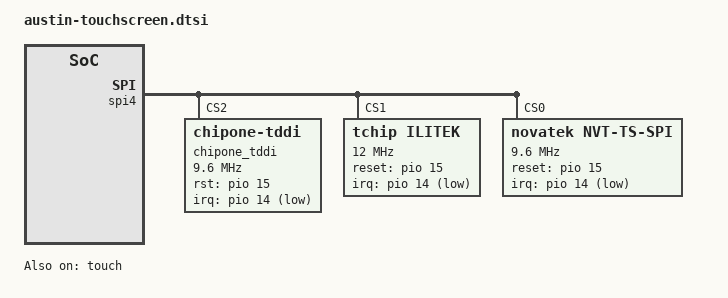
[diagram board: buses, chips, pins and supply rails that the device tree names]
/*
 * Copyright (C) 2010 - 2018 Novatek, Inc.
 *
 * $Revision$
 * $Date$
 *
 * This program is free software; you can redistribute it and/or modify
 * it under the terms of the GNU General Public License as published by
 * the Free Software Foundation; either version 2 of the License, or
 * (at your option) any later version.
 *
 * This program is distributed in the hope that it will be useful, but WITHOUT
 * ANY WARRANTY; without even the implied warranty of MERCHANTABILITY or
 * FITNESS FOR A PARTICULAR PURPOSE.  See the GNU General Public License for
 * more details.
 *
 */

&touch {
	tpd-resolution = <720 1600>;
	interrupt-parent = <&pio>;
	interrupts = <14 IRQ_TYPE_EDGE_RISING 14 0>;
	use-tpd-button = <0>;
	tpd-key-num = <3>;
	tpd-key-local= <139 172 158 0>;
	tpd-key-dim-local = <90 883 100 40 230
				 883 100 40 370 883 100 40 0 0 0 0>;
	tpd-max-touch-num = <10>;
	tpd-filter-enable = <0>;
	tpd-filter-pixel-density = <106>;
	tpd-filter-custom-prameters = <0 0 0 0 0 0 0 0 0 0 0 0>;
	tpd-filter-custom-speed = <0 0 0>;
	pinctrl-names = "default", "state_eint_as_int", "state_eint_output0",
		"state_eint_output1", "state_rst_output0", "state_rst_output1";
	pinctrl-0 = <&ctp_pins_default>;
	pinctrl-1 = <&ctp_pins_eint_as_int>;
	pinctrl-2 = <&ctp_pins_eint_output0>;
	pinctrl-3 = <&ctp_pins_eint_output1>;
	pinctrl-4 = <&ctp_pins_rst_output0>;
	pinctrl-5 = <&ctp_pins_rst_output1>;
	status = "okay";
};

&pio {
	ctp_pins_default: eint0default {
	};
	ctp_pins_eint_as_int: eint@0 {
		pins_cmd_dat {
			pinmux = <PINMUX_GPIO14__FUNC_GPIO14>;
			input-enable;
		};
	};
	ctp_pins_eint_output0: eintoutput0 {
		pins_cmd_dat {
			pinmux = <PINMUX_GPIO14__FUNC_GPIO14>;
			output-low;
		};
	};
	ctp_pins_eint_output1: eintoutput1 {
		pins_cmd_dat {
			pinmux = <PINMUX_GPIO14__FUNC_GPIO14>;
			output-high;
		};
	};
	ctp_pins_rst_output0: rstoutput0 {
		pins_cmd_dat {
			pinmux = <PINMUX_GPIO15__FUNC_GPIO15>;
			output-low;
		};
	};
	ctp_pins_rst_output1: rstoutput1 {
		pins_cmd_dat {
			pinmux = <PINMUX_GPIO15__FUNC_GPIO15>;
			output-high;
		};
	};
};

&spi4 {
	status = "okay";
	/delete-property/mediatek,pad-select;
	mediatek,pad-select = <0>,<0>,<0>;
	cs-gpios = <0>,<0>,<0>;

	chipone_tddi@2 {
		compatible = "chipone-tddi";
		reg = <2>;
		status = "okay";
		spi-max-frequency = <9600000>;
		chipone,rst-gpio = <&pio 15 0x00>;
		chipone,irq-gpio = <&pio 14 0x2001>;

		touch,max-touch-number = <10>;
		touch,display-coords =  <0 0 720 1600>;
		chipone,x-res = <720>;
		chipone,y-res = <1600>;

		chipone,test-reset-pin;
		chipone,test-rawdata;
		chipone,test-rawdata-frames = <1>;
		chipone,rawdata-min = <1560>;
		chipone,rawdata-max = <2860>;
		chipone,test-noise;
		chipone,test-noise-frames = <16>;
		chipone,noise-max = <70>;
		chipone,test-open;
		chipone,open-min = <3100>;
		chipone,test-short;
		chipone,short-min = <500>;

		chipone,test-compensate-cap;
		chipone,compensate-cap-min = <1>;
		chipone,compensate-cap-max = <126>;

		chipone,touch-charger-detect-enable;
		chipone,touch-charger-detect-type = "notify";
		chipone,touch-charger-detect-psy-name = "usb";
		chipone,touch-charger-detect-psp = "POWER_SUPPLY_PROP_ONLINE";
		chipone,touch-charger-detect-psp-poll-interval = <1000>;

		chipone,touch-earjack-detect-enable;
		chipone,touch-earjack-state-filepath = "/sys/bus/platform/drivers/Accdet_Driver/state";
		chipone,touch-earjack-poll-interval = <1000>;
	};

	ilitek@1{
		compatible = "tchip,ilitek";
		reg = <1>;
		spi-max-frequency = <12000000>;
		touch,reset-gpio = <&pio 15 0x00>;
		touch,irq-gpio = <&pio 14 0x2001>;

		status = "okay";
	};

	/* Novatek device tree node */
	novatek@0 {
		compatible = "novatek,NVT-ts-spi";
		reg = <0>; //Same as CS ID
		status = "ok";

		spi-max-frequency = <9600000>;	//4800000,9600000,15000000,19200000
		novatek,reset-gpio = <&pio 15 0x00>;
		novatek,irq-gpio = <&pio 14 0x2001>;

		/* 525 */
		//novatek,swrst-n8-addr = <0x01F01A>;

		/* 672A, 525B, 675, 526, 672C */
		novatek,swrst-n8-addr = <0x03F0FE>;
		novatek,spi-rd-fast-addr = <0x03F310>;

		/* MP */
		//novatek,mp-support-dt;

		novatek,def-config-id = <0x6503>;

		novatek-mp-criteria-nvtpid@0 {
			#address-cells = <1>;
			#size-cells = <0>;
			compatible = "novatek-mp-criteria-nvtpid";

			/* MP Config */
			IC_X_CFG_SIZE = <18>;
			IC_Y_CFG_SIZE = <36>;
			IC_KEY_CFG_SIZE = <4>;
			X_Channel = <18>;
			Y_Channel = <36>;
			AIN_X = <0 1 2 3 4 5 6 7 8 9 10 11 12 13 14 15 16 17>;
			AIN_Y = <0 1 2 3 4 5 6 7 8 9 10 11 12 13 14 15 16 17
						18 19 20 21 22 23 24 25 26 27 28 29 30 31 32 33 34 35>;
			AIN_KEY = <0 1 2 0xFF>;

			/* MP Criteria */
			PS_Config_Lmt_Short_Rawdata_P = <
				14008 14008 14008 14008 14008 14008 14008 14008 14008 14008 14008 14008 14008 14008 14008 14008 14008 14008
				14008 14008 14008 14008 14008 14008 14008 14008 14008 14008 14008 14008 14008 14008 14008 14008 14008 14008
				14008 14008 14008 14008 14008 14008 14008 14008 14008 14008 14008 14008 14008 14008 14008 14008 14008 14008
				14008 14008 14008 14008 14008 14008 14008 14008 14008 14008 14008 14008 14008 14008 14008 14008 14008 14008
				14008 14008 14008 14008 14008 14008 14008 14008 14008 14008 14008 14008 14008 14008 14008 14008 14008 14008
				14008 14008 14008 14008 14008 14008 14008 14008 14008 14008 14008 14008 14008 14008 14008 14008 14008 14008
				14008 14008 14008 14008 14008 14008 14008 14008 14008 14008 14008 14008 14008 14008 14008 14008 14008 14008
				14008 14008 14008 14008 14008 14008 14008 14008 14008 14008 14008 14008 14008 14008 14008 14008 14008 14008
				14008 14008 14008 14008 14008 14008 14008 14008 14008 14008 14008 14008 14008 14008 14008 14008 14008 14008
				14008 14008 14008 14008 14008 14008 14008 14008 14008 14008 14008 14008 14008 14008 14008 14008 14008 14008
				14008 14008 14008 14008 14008 14008 14008 14008 14008 14008 14008 14008 14008 14008 14008 14008 14008 14008
				14008 14008 14008 14008 14008 14008 14008 14008 14008 14008 14008 14008 14008 14008 14008 14008 14008 14008
				14008 14008 14008 14008 14008 14008 14008 14008 14008 14008 14008 14008 14008 14008 14008 14008 14008 14008
				14008 14008 14008 14008 14008 14008 14008 14008 14008 14008 14008 14008 14008 14008 14008 14008 14008 14008
				14008 14008 14008 14008 14008 14008 14008 14008 14008 14008 14008 14008 14008 14008 14008 14008 14008 14008
				14008 14008 14008 14008 14008 14008 14008 14008 14008 14008 14008 14008 14008 14008 14008 14008 14008 14008
				14008 14008 14008 14008 14008 14008 14008 14008 14008 14008 14008 14008 14008 14008 14008 14008 14008 14008
				14008 14008 14008 14008 14008 14008 14008 14008 14008 14008 14008 14008 14008 14008 14008 14008 14008 14008
				14008 14008 14008 14008 14008 14008 14008 14008 14008 14008 14008 14008 14008 14008 14008 14008 14008 14008
				14008 14008 14008 14008 14008 14008 14008 14008 14008 14008 14008 14008 14008 14008 14008 14008 14008 14008
				14008 14008 14008 14008 14008 14008 14008 14008 14008 14008 14008 14008 14008 14008 14008 14008 14008 14008
				14008 14008 14008 14008 14008 14008 14008 14008 14008 14008 14008 14008 14008 14008 14008 14008 14008 14008
				14008 14008 14008 14008 14008 14008 14008 14008 14008 14008 14008 14008 14008 14008 14008 14008 14008 14008
				14008 14008 14008 14008 14008 14008 14008 14008 14008 14008 14008 14008 14008 14008 14008 14008 14008 14008
				14008 14008 14008 14008 14008 14008 14008 14008 14008 14008 14008 14008 14008 14008 14008 14008 14008 14008
				14008 14008 14008 14008 14008 14008 14008 14008 14008 14008 14008 14008 14008 14008 14008 14008 14008 14008
				14008 14008 14008 14008 14008 14008 14008 14008 14008 14008 14008 14008 14008 14008 14008 14008 14008 14008
				14008 14008 14008 14008 14008 14008 14008 14008 14008 14008 14008 14008 14008 14008 14008 14008 14008 14008
				14008 14008 14008 14008 14008 14008 14008 14008 14008 14008 14008 14008 14008 14008 14008 14008 14008 14008
				14008 14008 14008 14008 14008 14008 14008 14008 14008 14008 14008 14008 14008 14008 14008 14008 14008 14008
				14008 14008 14008 14008 14008 14008 14008 14008 14008 14008 14008 14008 14008 14008 14008 14008 14008 14008
				14008 14008 14008 14008 14008 14008 14008 14008 14008 14008 14008 14008 14008 14008 14008 14008 14008 14008
				14008 14008 14008 14008 14008 14008 14008 14008 14008 14008 14008 14008 14008 14008 14008 14008 14008 14008
				14008 14008 14008 14008 14008 14008 14008 14008 14008 14008 14008 14008 14008 14008 14008 14008 14008 14008
				14008 14008 14008 14008 14008 14008 14008 14008 14008 14008 14008 14008 14008 14008 14008 14008 14008 14008
				14008 14008 14008 14008 14008 14008 14008 14008 14008 14008 14008 14008 14008 14008 14008 14008 14008 14008
				14008 14008 14008>;

			PS_Config_Lmt_Short_Rawdata_N = <
				10000 10000 10000 10000 10000 10000 10000 10000 10000 10000 10000 10000 10000 10000 10000 10000 10000 10000
				10000 10000 10000 10000 10000 10000 10000 10000 10000 10000 10000 10000 10000 10000 10000 10000 10000 10000
				10000 10000 10000 10000 10000 10000 10000 10000 10000 10000 10000 10000 10000 10000 10000 10000 10000 10000
				10000 10000 10000 10000 10000 10000 10000 10000 10000 10000 10000 10000 10000 10000 10000 10000 10000 10000
				10000 10000 10000 10000 10000 10000 10000 10000 10000 10000 10000 10000 10000 10000 10000 10000 10000 10000
				10000 10000 10000 10000 10000 10000 10000 10000 10000 10000 10000 10000 10000 10000 10000 10000 10000 10000
				10000 10000 10000 10000 10000 10000 10000 10000 10000 10000 10000 10000 10000 10000 10000 10000 10000 10000
				10000 10000 10000 10000 10000 10000 10000 10000 10000 10000 10000 10000 10000 10000 10000 10000 10000 10000
				10000 10000 10000 10000 10000 10000 10000 10000 10000 10000 10000 10000 10000 10000 10000 10000 10000 10000
				10000 10000 10000 10000 10000 10000 10000 10000 10000 10000 10000 10000 10000 10000 10000 10000 10000 10000
				10000 10000 10000 10000 10000 10000 10000 10000 10000 10000 10000 10000 10000 10000 10000 10000 10000 10000
				10000 10000 10000 10000 10000 10000 10000 10000 10000 10000 10000 10000 10000 10000 10000 10000 10000 10000
				10000 10000 10000 10000 10000 10000 10000 10000 10000 10000 10000 10000 10000 10000 10000 10000 10000 10000
				10000 10000 10000 10000 10000 10000 10000 10000 10000 10000 10000 10000 10000 10000 10000 10000 10000 10000
				10000 10000 10000 10000 10000 10000 10000 10000 10000 10000 10000 10000 10000 10000 10000 10000 10000 10000
				10000 10000 10000 10000 10000 10000 10000 10000 10000 10000 10000 10000 10000 10000 10000 10000 10000 10000
				10000 10000 10000 10000 10000 10000 10000 10000 10000 10000 10000 10000 10000 10000 10000 10000 10000 10000
				10000 10000 10000 10000 10000 10000 10000 10000 10000 10000 10000 10000 10000 10000 10000 10000 10000 10000
				10000 10000 10000 10000 10000 10000 10000 10000 10000 10000 10000 10000 10000 10000 10000 10000 10000 10000
				10000 10000 10000 10000 10000 10000 10000 10000 10000 10000 10000 10000 10000 10000 10000 10000 10000 10000
				10000 10000 10000 10000 10000 10000 10000 10000 10000 10000 10000 10000 10000 10000 10000 10000 10000 10000
				10000 10000 10000 10000 10000 10000 10000 10000 10000 10000 10000 10000 10000 10000 10000 10000 10000 10000
				10000 10000 10000 10000 10000 10000 10000 10000 10000 10000 10000 10000 10000 10000 10000 10000 10000 10000
				10000 10000 10000 10000 10000 10000 10000 10000 10000 10000 10000 10000 10000 10000 10000 10000 10000 10000
				10000 10000 10000 10000 10000 10000 10000 10000 10000 10000 10000 10000 10000 10000 10000 10000 10000 10000
				10000 10000 10000 10000 10000 10000 10000 10000 10000 10000 10000 10000 10000 10000 10000 10000 10000 10000
				10000 10000 10000 10000 10000 10000 10000 10000 10000 10000 10000 10000 10000 10000 10000 10000 10000 10000
				10000 10000 10000 10000 10000 10000 10000 10000 10000 10000 10000 10000 10000 10000 10000 10000 10000 10000
				10000 10000 10000 10000 10000 10000 10000 10000 10000 10000 10000 10000 10000 10000 10000 10000 10000 10000
				10000 10000 10000 10000 10000 10000 10000 10000 10000 10000 10000 10000 10000 10000 10000 10000 10000 10000
				10000 10000 10000 10000 10000 10000 10000 10000 10000 10000 10000 10000 10000 10000 10000 10000 10000 10000
				10000 10000 10000 10000 10000 10000 10000 10000 10000 10000 10000 10000 10000 10000 10000 10000 10000 10000
				10000 10000 10000 10000 10000 10000 10000 10000 10000 10000 10000 10000 10000 10000 10000 10000 10000 10000
				10000 10000 10000 10000 10000 10000 10000 10000 10000 10000 10000 10000 10000 10000 10000 10000 10000 10000
				10000 10000 10000 10000 10000 10000 10000 10000 10000 10000 10000 10000 10000 10000 10000 10000 10000 10000
				10000 10000 10000 10000 10000 10000 10000 10000 10000 10000 10000 10000 10000 10000 10000 10000 10000 10000
				10000 10000 10000>;

			PS_Config_Lmt_Open_Rawdata_P = <
				5120 5120 5120 5120 5120 5120 5120 5120 5120 5120 5120 5120 5120 5120 5120 5120 5120 5120
				5120 5120 5120 5120 5120 5120 5120 5120 5120 5120 5120 5120 5120 5120 5120 5120 5120 5120
				5120 5120 5120 5120 5120 5120 5120 5120 5120 5120 5120 5120 5120 5120 5120 5120 5120 5120
				5120 5120 5120 5120 5120 5120 5120 5120 5120 5120 5120 5120 5120 5120 5120 5120 5120 5120
				5120 5120 5120 5120 5120 5120 5120 5120 5120 5120 5120 5120 5120 5120 5120 5120 5120 5120
				5120 5120 5120 5120 5120 5120 5120 5120 5120 5120 5120 5120 5120 5120 5120 5120 5120 5120
				5120 5120 5120 5120 5120 5120 5120 5120 5120 5120 5120 5120 5120 5120 5120 5120 5120 5120
				5120 5120 5120 5120 5120 5120 5120 5120 5120 5120 5120 5120 5120 5120 5120 5120 5120 5120
				5120 5120 5120 5120 5120 5120 5120 5120 5120 5120 5120 5120 5120 5120 5120 5120 5120 5120
				5120 5120 5120 5120 5120 5120 5120 5120 5120 5120 5120 5120 5120 5120 5120 5120 5120 5120
				5120 5120 5120 5120 5120 5120 5120 5120 5120 5120 5120 5120 5120 5120 5120 5120 5120 5120
				5120 5120 5120 5120 5120 5120 5120 5120 5120 5120 5120 5120 5120 5120 5120 5120 5120 5120
				5120 5120 5120 5120 5120 5120 5120 5120 5120 5120 5120 5120 5120 5120 5120 5120 5120 5120
				5120 5120 5120 5120 5120 5120 5120 5120 5120 5120 5120 5120 5120 5120 5120 5120 5120 5120
				5120 5120 5120 5120 5120 5120 5120 5120 5120 5120 5120 5120 5120 5120 5120 5120 5120 5120
				5120 5120 5120 5120 5120 5120 5120 5120 5120 5120 5120 5120 5120 5120 5120 5120 5120 5120
				5120 5120 5120 5120 5120 5120 5120 5120 5120 5120 5120 5120 5120 5120 5120 5120 5120 5120
				5120 5120 5120 5120 5120 5120 5120 5120 5120 5120 5120 5120 5120 5120 5120 5120 5120 5120
				5120 5120 5120 5120 5120 5120 5120 5120 5120 5120 5120 5120 5120 5120 5120 5120 5120 5120
				5120 5120 5120 5120 5120 5120 5120 5120 5120 5120 5120 5120 5120 5120 5120 5120 5120 5120
				5120 5120 5120 5120 5120 5120 5120 5120 5120 5120 5120 5120 5120 5120 5120 5120 5120 5120
				5120 5120 5120 5120 5120 5120 5120 5120 5120 5120 5120 5120 5120 5120 5120 5120 5120 5120
				5120 5120 5120 5120 5120 5120 5120 5120 5120 5120 5120 5120 5120 5120 5120 5120 5120 5120
				5120 5120 5120 5120 5120 5120 5120 5120 5120 5120 5120 5120 5120 5120 5120 5120 5120 5120
				5120 5120 5120 5120 5120 5120 5120 5120 5120 5120 5120 5120 5120 5120 5120 5120 5120 5120
				5120 5120 5120 5120 5120 5120 5120 5120 5120 5120 5120 5120 5120 5120 5120 5120 5120 5120
				5120 5120 5120 5120 5120 5120 5120 5120 5120 5120 5120 5120 5120 5120 5120 5120 5120 5120
				5120 5120 5120 5120 5120 5120 5120 5120 5120 5120 5120 5120 5120 5120 5120 5120 5120 5120
				5120 5120 5120 5120 5120 5120 5120 5120 5120 5120 5120 5120 5120 5120 5120 5120 5120 5120
				5120 5120 5120 5120 5120 5120 5120 5120 5120 5120 5120 5120 5120 5120 5120 5120 5120 5120
				5120 5120 5120 5120 5120 5120 5120 5120 5120 5120 5120 5120 5120 5120 5120 5120 5120 5120
				5120 5120 5120 5120 5120 5120 5120 5120 5120 5120 5120 5120 5120 5120 5120 5120 5120 5120
				5120 5120 5120 5120 5120 5120 5120 5120 5120 5120 5120 5120 5120 5120 5120 5120 5120 5120
				5120 5120 5120 5120 5120 5120 5120 5120 5120 5120 5120 5120 5120 5120 5120 5120 5120 5120
				5120 5120 5120 5120 5120 5120 5120 5120 5120 5120 5120 5120 5120 5120 5120 5120 5120 5120
				5120 5120 5120 5120 5120 5120 5120 5120 5120 5120 5120 5120 5120 5120 5120 5120 5120 5120
				5120 5120 5120>;

			PS_Config_Lmt_Open_Rawdata_N = <
				(-511) (-511) (-511) (-511) (-511) (-511) (-511) (-511) (-511) (-511) (-511) (-511) (-511) (-511) (-511) (-511) (-511) (-511)
				(-511) (-511) (-511) (-511) (-511) (-511) (-511) (-511) (-511) (-511) (-511) (-511) (-511) (-511) (-511) (-511) (-511) (-511)
				(-511) (-511) (-511) (-511) (-511) (-511) (-511) (-511) (-511) (-511) (-511) (-511) (-511) (-511) (-511) (-511) (-511) (-511)
				(-511) (-511) (-511) (-511) (-511) (-511) (-511) (-511) (-511) (-511) (-511) (-511) (-511) (-511) (-511) (-511) (-511) (-511)
				(-511) (-511) (-511) (-511) (-511) (-511) (-511) (-511) (-511) (-511) (-511) (-511) (-511) (-511) (-511) (-511) (-511) (-511)
				(-511) (-511) (-511) (-511) (-511) (-511) (-511) (-511) (-511) (-511) (-511) (-511) (-511) (-511) (-511) (-511) (-511) (-511)
				(-511) (-511) (-511) (-511) (-511) (-511) (-511) (-511) (-511) (-511) (-511) (-511) (-511) (-511) (-511) (-511) (-511) (-511)
				(-511) (-511) (-511) (-511) (-511) (-511) (-511) (-511) (-511) (-511) (-511) (-511) (-511) (-511) (-511) (-511) (-511) (-511)
				(-511) (-511) (-511) (-511) (-511) (-511) (-511) (-511) (-511) (-511) (-511) (-511) (-511) (-511) (-511) (-511) (-511) (-511)
				(-511) (-511) (-511) (-511) (-511) (-511) (-511) (-511) (-511) (-511) (-511) (-511) (-511) (-511) (-511) (-511) (-511) (-511)
				(-511) (-511) (-511) (-511) (-511) (-511) (-511) (-511) (-511) (-511) (-511) (-511) (-511) (-511) (-511) (-511) (-511) (-511)
				(-511) (-511) (-511) (-511) (-511) (-511) (-511) (-511) (-511) (-511) (-511) (-511) (-511) (-511) (-511) (-511) (-511) (-511)
				(-511) (-511) (-511) (-511) (-511) (-511) (-511) (-511) (-511) (-511) (-511) (-511) (-511) (-511) (-511) (-511) (-511) (-511)
				(-511) (-511) (-511) (-511) (-511) (-511) (-511) (-511) (-511) (-511) (-511) (-511) (-511) (-511) (-511) (-511) (-511) (-511)
				(-511) (-511) (-511) (-511) (-511) (-511) (-511) (-511) (-511) (-511) (-511) (-511) (-511) (-511) (-511) (-511) (-511) (-511)
				(-511) (-511) (-511) (-511) (-511) (-511) (-511) (-511) (-511) (-511) (-511) (-511) (-511) (-511) (-511) (-511) (-511) (-511)
				(-511) (-511) (-511) (-511) (-511) (-511) (-511) (-511) (-511) (-511) (-511) (-511) (-511) (-511) (-511) (-511) (-511) (-511)
				(-511) (-511) (-511) (-511) (-511) (-511) (-511) (-511) (-511) (-511) (-511) (-511) (-511) (-511) (-511) (-511) (-511) (-511)
				(-511) (-511) (-511) (-511) (-511) (-511) (-511) (-511) (-511) (-511) (-511) (-511) (-511) (-511) (-511) (-511) (-511) (-511)
				(-511) (-511) (-511) (-511) (-511) (-511) (-511) (-511) (-511) (-511) (-511) (-511) (-511) (-511) (-511) (-511) (-511) (-511)
				(-511) (-511) (-511) (-511) (-511) (-511) (-511) (-511) (-511) (-511) (-511) (-511) (-511) (-511) (-511) (-511) (-511) (-511)
				(-511) (-511) (-511) (-511) (-511) (-511) (-511) (-511) (-511) (-511) (-511) (-511) (-511) (-511) (-511) (-511) (-511) (-511)
				(-511) (-511) (-511) (-511) (-511) (-511) (-511) (-511) (-511) (-511) (-511) (-511) (-511) (-511) (-511) (-511) (-511) (-511)
				(-511) (-511) (-511) (-511) (-511) (-511) (-511) (-511) (-511) (-511) (-511) (-511) (-511) (-511) (-511) (-511) (-511) (-511)
				(-511) (-511) (-511) (-511) (-511) (-511) (-511) (-511) (-511) (-511) (-511) (-511) (-511) (-511) (-511) (-511) (-511) (-511)
				(-511) (-511) (-511) (-511) (-511) (-511) (-511) (-511) (-511) (-511) (-511) (-511) (-511) (-511) (-511) (-511) (-511) (-511)
				(-511) (-511) (-511) (-511) (-511) (-511) (-511) (-511) (-511) (-511) (-511) (-511) (-511) (-511) (-511) (-511) (-511) (-511)
				(-511) (-511) (-511) (-511) (-511) (-511) (-511) (-511) (-511) (-511) (-511) (-511) (-511) (-511) (-511) (-511) (-511) (-511)
				(-511) (-511) (-511) (-511) (-511) (-511) (-511) (-511) (-511) (-511) (-511) (-511) (-511) (-511) (-511) (-511) (-511) (-511)
				(-511) (-511) (-511) (-511) (-511) (-511) (-511) (-511) (-511) (-511) (-511) (-511) (-511) (-511) (-511) (-511) (-511) (-511)
				(-511) (-511) (-511) (-511) (-511) (-511) (-511) (-511) (-511) (-511) (-511) (-511) (-511) (-511) (-511) (-511) (-511) (-511)
				(-511) (-511) (-511) (-511) (-511) (-511) (-511) (-511) (-511) (-511) (-511) (-511) (-511) (-511) (-511) (-511) (-511) (-511)
				(-511) (-511) (-511) (-511) (-511) (-511) (-511) (-511) (-511) (-511) (-511) (-511) (-511) (-511) (-511) (-511) (-511) (-511)
				(-511) (-511) (-511) (-511) (-511) (-511) (-511) (-511) (-511) (-511) (-511) (-511) (-511) (-511) (-511) (-511) (-511) (-511)
				(-511) (-511) (-511) (-511) (-511) (-511) (-511) (-511) (-511) (-511) (-511) (-511) (-511) (-511) (-511) (-511) (-511) (-511)
				(-511) (-511) (-511) (-511) (-511) (-511) (-511) (-511) (-511) (-511) (-511) (-511) (-511) (-511) (-511) (-511) (-511) (-511)
				(-511) (-511) (-511)>;

			PS_Config_Lmt_FW_Rawdata_P = <
				2560 2560 2560 2560 2560 2560 2560 2560 2560 2560 2560 2560 2560 2560 2560 2560 2560 2560
				2560 2560 2560 2560 2560 2560 2560 2560 2560 2560 2560 2560 2560 2560 2560 2560 2560 2560
				2560 2560 2560 2560 2560 2560 2560 2560 2560 2560 2560 2560 2560 2560 2560 2560 2560 2560
				2560 2560 2560 2560 2560 2560 2560 2560 2560 2560 2560 2560 2560 2560 2560 2560 2560 2560
				2560 2560 2560 2560 2560 2560 2560 2560 2560 2560 2560 2560 2560 2560 2560 2560 2560 2560
				2560 2560 2560 2560 2560 2560 2560 2560 2560 2560 2560 2560 2560 2560 2560 2560 2560 2560
				2560 2560 2560 2560 2560 2560 2560 2560 2560 2560 2560 2560 2560 2560 2560 2560 2560 2560
				2560 2560 2560 2560 2560 2560 2560 2560 2560 2560 2560 2560 2560 2560 2560 2560 2560 2560
				2560 2560 2560 2560 2560 2560 2560 2560 2560 2560 2560 2560 2560 2560 2560 2560 2560 2560
				2560 2560 2560 2560 2560 2560 2560 2560 2560 2560 2560 2560 2560 2560 2560 2560 2560 2560
				2560 2560 2560 2560 2560 2560 2560 2560 2560 2560 2560 2560 2560 2560 2560 2560 2560 2560
				2560 2560 2560 2560 2560 2560 2560 2560 2560 2560 2560 2560 2560 2560 2560 2560 2560 2560
				2560 2560 2560 2560 2560 2560 2560 2560 2560 2560 2560 2560 2560 2560 2560 2560 2560 2560
				2560 2560 2560 2560 2560 2560 2560 2560 2560 2560 2560 2560 2560 2560 2560 2560 2560 2560
				2560 2560 2560 2560 2560 2560 2560 2560 2560 2560 2560 2560 2560 2560 2560 2560 2560 2560
				2560 2560 2560 2560 2560 2560 2560 2560 2560 2560 2560 2560 2560 2560 2560 2560 2560 2560
				2560 2560 2560 2560 2560 2560 2560 2560 2560 2560 2560 2560 2560 2560 2560 2560 2560 2560
				2560 2560 2560 2560 2560 2560 2560 2560 2560 2560 2560 2560 2560 2560 2560 2560 2560 2560
				2560 2560 2560 2560 2560 2560 2560 2560 2560 2560 2560 2560 2560 2560 2560 2560 2560 2560
				2560 2560 2560 2560 2560 2560 2560 2560 2560 2560 2560 2560 2560 2560 2560 2560 2560 2560
				2560 2560 2560 2560 2560 2560 2560 2560 2560 2560 2560 2560 2560 2560 2560 2560 2560 2560
				2560 2560 2560 2560 2560 2560 2560 2560 2560 2560 2560 2560 2560 2560 2560 2560 2560 2560
				2560 2560 2560 2560 2560 2560 2560 2560 2560 2560 2560 2560 2560 2560 2560 2560 2560 2560
				2560 2560 2560 2560 2560 2560 2560 2560 2560 2560 2560 2560 2560 2560 2560 2560 2560 2560
				2560 2560 2560 2560 2560 2560 2560 2560 2560 2560 2560 2560 2560 2560 2560 2560 2560 2560
				2560 2560 2560 2560 2560 2560 2560 2560 2560 2560 2560 2560 2560 2560 2560 2560 2560 2560
				2560 2560 2560 2560 2560 2560 2560 2560 2560 2560 2560 2560 2560 2560 2560 2560 2560 2560
				2560 2560 2560 2560 2560 2560 2560 2560 2560 2560 2560 2560 2560 2560 2560 2560 2560 2560
				2560 2560 2560 2560 2560 2560 2560 2560 2560 2560 2560 2560 2560 2560 2560 2560 2560 2560
				2560 2560 2560 2560 2560 2560 2560 2560 2560 2560 2560 2560 2560 2560 2560 2560 2560 2560
				2560 2560 2560 2560 2560 2560 2560 2560 2560 2560 2560 2560 2560 2560 2560 2560 2560 2560
				2560 2560 2560 2560 2560 2560 2560 2560 2560 2560 2560 2560 2560 2560 2560 2560 2560 2560
				2560 2560 2560 2560 2560 2560 2560 2560 2560 2560 2560 2560 2560 2560 2560 2560 2560 2560
				2560 2560 2560 2560 2560 2560 2560 2560 2560 2560 2560 2560 2560 2560 2560 2560 2560 2560
				2560 2560 2560 2560 2560 2560 2560 2560 2560 2560 2560 2560 2560 2560 2560 2560 2560 2560
				2560 2560 2560 2560 2560 2560 2560 2560 2560 2560 2560 2560 2560 2560 2560 2560 2560 2560
				2560 2560 2560>;

			PS_Config_Lmt_FW_Rawdata_N = <
				240 240 240 240 240 240 240 240 240 240 240 240 240 240 240 240 240 240
				240 240 240 240 240 240 240 240 240 240 240 240 240 240 240 240 240 240
				240 240 240 240 240 240 240 240 240 240 240 240 240 240 240 240 240 240
				240 240 240 240 240 240 240 240 240 240 240 240 240 240 240 240 240 240
				240 240 240 240 240 240 240 240 240 240 240 240 240 240 240 240 240 240
				240 240 240 240 240 240 240 240 240 240 240 240 240 240 240 240 240 240
				240 240 240 240 240 240 240 240 240 240 240 240 240 240 240 240 240 240
				240 240 240 240 240 240 240 240 240 240 240 240 240 240 240 240 240 240
				240 240 240 240 240 240 240 240 240 240 240 240 240 240 240 240 240 240
				240 240 240 240 240 240 240 240 240 240 240 240 240 240 240 240 240 240
				240 240 240 240 240 240 240 240 240 240 240 240 240 240 240 240 240 240
				240 240 240 240 240 240 240 240 240 240 240 240 240 240 240 240 240 240
				240 240 240 240 240 240 240 240 240 240 240 240 240 240 240 240 240 240
				240 240 240 240 240 240 240 240 240 240 240 240 240 240 240 240 240 240
				240 240 240 240 240 240 240 240 240 240 240 240 240 240 240 240 240 240
				240 240 240 240 240 240 240 240 240 240 240 240 240 240 240 240 240 240
				240 240 240 240 240 240 240 240 240 240 240 240 240 240 240 240 240 240
				240 240 240 240 240 240 240 240 240 240 240 240 240 240 240 240 240 240
				240 240 240 240 240 240 240 240 240 240 240 240 240 240 240 240 240 240
				240 240 240 240 240 240 240 240 240 240 240 240 240 240 240 240 240 240
				240 240 240 240 240 240 240 240 240 240 240 240 240 240 240 240 240 240
				240 240 240 240 240 240 240 240 240 240 240 240 240 240 240 240 240 240
				240 240 240 240 240 240 240 240 240 240 240 240 240 240 240 240 240 240
				240 240 240 240 240 240 240 240 240 240 240 240 240 240 240 240 240 240
				240 240 240 240 240 240 240 240 240 240 240 240 240 240 240 240 240 240
				240 240 240 240 240 240 240 240 240 240 240 240 240 240 240 240 240 240
				240 240 240 240 240 240 240 240 240 240 240 240 240 240 240 240 240 240
				240 240 240 240 240 240 240 240 240 240 240 240 240 240 240 240 240 240
				240 240 240 240 240 240 240 240 240 240 240 240 240 240 240 240 240 240
				240 240 240 240 240 240 240 240 240 240 240 240 240 240 240 240 240 240
				240 240 240 240 240 240 240 240 240 240 240 240 240 240 240 240 240 240
				240 240 240 240 240 240 240 240 240 240 240 240 240 240 240 240 240 240
				240 240 240 240 240 240 240 240 240 240 240 240 240 240 240 240 240 240
				240 240 240 240 240 240 240 240 240 240 240 240 240 240 240 240 240 240
				240 240 240 240 240 240 240 240 240 240 240 240 240 240 240 240 240 240
				240 240 240 240 240 240 240 240 240 240 240 240 240 240 240 240 240 240
				240 240 240>;

			PS_Config_Lmt_FW_CC_P = <
				314 314 314 314 314 314 314 314 314 314 314 314 314 314 314 314 314 314
				314 314 314 314 314 314 314 314 314 314 314 314 314 314 314 314 314 314
				314 314 314 314 314 314 314 314 314 314 314 314 314 314 314 314 314 314
				314 314 314 314 314 314 314 314 314 314 314 314 314 314 314 314 314 314
				314 314 314 314 314 314 314 314 314 314 314 314 314 314 314 314 314 314
				314 314 314 314 314 314 314 314 314 314 314 314 314 314 314 314 314 314
				314 314 314 314 314 314 314 314 314 314 314 314 314 314 314 314 314 314
				314 314 314 314 314 314 314 314 314 314 314 314 314 314 314 314 314 314
				314 314 314 314 314 314 314 314 314 314 314 314 314 314 314 314 314 314
				314 314 314 314 314 314 314 314 314 314 314 314 314 314 314 314 314 314
				314 314 314 314 314 314 314 314 314 314 314 314 314 314 314 314 314 314
				314 314 314 314 314 314 314 314 314 314 314 314 314 314 314 314 314 314
				314 314 314 314 314 314 314 314 314 314 314 314 314 314 314 314 314 314
				314 314 314 314 314 314 314 314 314 314 314 314 314 314 314 314 314 314
				314 314 314 314 314 314 314 314 314 314 314 314 314 314 314 314 314 314
				314 314 314 314 314 314 314 314 314 314 314 314 314 314 314 314 314 314
				314 314 314 314 314 314 314 314 314 314 314 314 314 314 314 314 314 314
				314 314 314 314 314 314 314 314 314 314 314 314 314 314 314 314 314 314
				314 314 314 314 314 314 314 314 314 314 314 314 314 314 314 314 314 314
				314 314 314 314 314 314 314 314 314 314 314 314 314 314 314 314 314 314
				314 314 314 314 314 314 314 314 314 314 314 314 314 314 314 314 314 314
				314 314 314 314 314 314 314 314 314 314 314 314 314 314 314 314 314 314
				314 314 314 314 314 314 314 314 314 314 314 314 314 314 314 314 314 314
				314 314 314 314 314 314 314 314 314 314 314 314 314 314 314 314 314 314
				314 314 314 314 314 314 314 314 314 314 314 314 314 314 314 314 314 314
				314 314 314 314 314 314 314 314 314 314 314 314 314 314 314 314 314 314
				314 314 314 314 314 314 314 314 314 314 314 314 314 314 314 314 314 314
				314 314 314 314 314 314 314 314 314 314 314 314 314 314 314 314 314 314
				314 314 314 314 314 314 314 314 314 314 314 314 314 314 314 314 314 314
				314 314 314 314 314 314 314 314 314 314 314 314 314 314 314 314 314 314
				314 314 314 314 314 314 314 314 314 314 314 314 314 314 314 314 314 314
				314 314 314 314 314 314 314 314 314 314 314 314 314 314 314 314 314 314
				314 314 314 314 314 314 314 314 314 314 314 314 314 314 314 314 314 314
				314 314 314 314 314 314 314 314 314 314 314 314 314 314 314 314 314 314
				314 314 314 314 314 314 314 314 314 314 314 314 314 314 314 314 314 314
				314 314 314 314 314 314 314 314 314 314 314 314 314 314 314 314 314 314
				314 314 314>;

			PS_Config_Lmt_FW_CC_N = <
				0 0 0 0 0 0 0 0 0 0 0 0 0 0 0 0 0 0
				0 0 0 0 0 0 0 0 0 0 0 0 0 0 0 0 0 0
				0 0 0 0 0 0 0 0 0 0 0 0 0 0 0 0 0 0
				0 0 0 0 0 0 0 0 0 0 0 0 0 0 0 0 0 0
				0 0 0 0 0 0 0 0 0 0 0 0 0 0 0 0 0 0
				0 0 0 0 0 0 0 0 0 0 0 0 0 0 0 0 0 0
				0 0 0 0 0 0 0 0 0 0 0 0 0 0 0 0 0 0
				0 0 0 0 0 0 0 0 0 0 0 0 0 0 0 0 0 0
				0 0 0 0 0 0 0 0 0 0 0 0 0 0 0 0 0 0
				0 0 0 0 0 0 0 0 0 0 0 0 0 0 0 0 0 0
				0 0 0 0 0 0 0 0 0 0 0 0 0 0 0 0 0 0
				0 0 0 0 0 0 0 0 0 0 0 0 0 0 0 0 0 0
				0 0 0 0 0 0 0 0 0 0 0 0 0 0 0 0 0 0
				0 0 0 0 0 0 0 0 0 0 0 0 0 0 0 0 0 0
				0 0 0 0 0 0 0 0 0 0 0 0 0 0 0 0 0 0
				0 0 0 0 0 0 0 0 0 0 0 0 0 0 0 0 0 0
				0 0 0 0 0 0 0 0 0 0 0 0 0 0 0 0 0 0
				0 0 0 0 0 0 0 0 0 0 0 0 0 0 0 0 0 0
				0 0 0 0 0 0 0 0 0 0 0 0 0 0 0 0 0 0
				0 0 0 0 0 0 0 0 0 0 0 0 0 0 0 0 0 0
				0 0 0 0 0 0 0 0 0 0 0 0 0 0 0 0 0 0
				0 0 0 0 0 0 0 0 0 0 0 0 0 0 0 0 0 0
				0 0 0 0 0 0 0 0 0 0 0 0 0 0 0 0 0 0
				0 0 0 0 0 0 0 0 0 0 0 0 0 0 0 0 0 0
				0 0 0 0 0 0 0 0 0 0 0 0 0 0 0 0 0 0
				0 0 0 0 0 0 0 0 0 0 0 0 0 0 0 0 0 0
				0 0 0 0 0 0 0 0 0 0 0 0 0 0 0 0 0 0
				0 0 0 0 0 0 0 0 0 0 0 0 0 0 0 0 0 0
				0 0 0 0 0 0 0 0 0 0 0 0 0 0 0 0 0 0
				0 0 0 0 0 0 0 0 0 0 0 0 0 0 0 0 0 0
				0 0 0 0 0 0 0 0 0 0 0 0 0 0 0 0 0 0
				0 0 0 0 0 0 0 0 0 0 0 0 0 0 0 0 0 0
				0 0 0 0 0 0 0 0 0 0 0 0 0 0 0 0 0 0
				0 0 0 0 0 0 0 0 0 0 0 0 0 0 0 0 0 0
				0 0 0 0 0 0 0 0 0 0 0 0 0 0 0 0 0 0
				0 0 0 0 0 0 0 0 0 0 0 0 0 0 0 0 0 0
				0 0 0>;

			PS_Config_Lmt_FW_Diff_P = <
				75 75 75 75 75 75 75 75 75 75 75 75 75 75 75 75 75 75
				75 75 75 75 75 75 75 75 75 75 75 75 75 75 75 75 75 75
				75 75 75 75 75 75 75 75 75 75 75 75 75 75 75 75 75 75
				75 75 75 75 75 75 75 75 75 75 75 75 75 75 75 75 75 75
				75 75 75 75 75 75 75 75 75 75 75 75 75 75 75 75 75 75
				75 75 75 75 75 75 75 75 75 75 75 75 75 75 75 75 75 75
				75 75 75 75 75 75 75 75 75 75 75 75 75 75 75 75 75 75
				75 75 75 75 75 75 75 75 75 75 75 75 75 75 75 75 75 75
				75 75 75 75 75 75 75 75 75 75 75 75 75 75 75 75 75 75
				75 75 75 75 75 75 75 75 75 75 75 75 75 75 75 75 75 75
				75 75 75 75 75 75 75 75 75 75 75 75 75 75 75 75 75 75
				75 75 75 75 75 75 75 75 75 75 75 75 75 75 75 75 75 75
				75 75 75 75 75 75 75 75 75 75 75 75 75 75 75 75 75 75
				75 75 75 75 75 75 75 75 75 75 75 75 75 75 75 75 75 75
				75 75 75 75 75 75 75 75 75 75 75 75 75 75 75 75 75 75
				75 75 75 75 75 75 75 75 75 75 75 75 75 75 75 75 75 75
				75 75 75 75 75 75 75 75 75 75 75 75 75 75 75 75 75 75
				75 75 75 75 75 75 75 75 75 75 75 75 75 75 75 75 75 75
				75 75 75 75 75 75 75 75 75 75 75 75 75 75 75 75 75 75
				75 75 75 75 75 75 75 75 75 75 75 75 75 75 75 75 75 75
				75 75 75 75 75 75 75 75 75 75 75 75 75 75 75 75 75 75
				75 75 75 75 75 75 75 75 75 75 75 75 75 75 75 75 75 75
				75 75 75 75 75 75 75 75 75 75 75 75 75 75 75 75 75 75
				75 75 75 75 75 75 75 75 75 75 75 75 75 75 75 75 75 75
				75 75 75 75 75 75 75 75 75 75 75 75 75 75 75 75 75 75
				75 75 75 75 75 75 75 75 75 75 75 75 75 75 75 75 75 75
				75 75 75 75 75 75 75 75 75 75 75 75 75 75 75 75 75 75
				75 75 75 75 75 75 75 75 75 75 75 75 75 75 75 75 75 75
				75 75 75 75 75 75 75 75 75 75 75 75 75 75 75 75 75 75
				75 75 75 75 75 75 75 75 75 75 75 75 75 75 75 75 75 75
				75 75 75 75 75 75 75 75 75 75 75 75 75 75 75 75 75 75
				75 75 75 75 75 75 75 75 75 75 75 75 75 75 75 75 75 75
				75 75 75 75 75 75 75 75 75 75 75 75 75 75 75 75 75 75
				75 75 75 75 75 75 75 75 75 75 75 75 75 75 75 75 75 75
				75 75 75 75 75 75 75 75 75 75 75 75 75 75 75 75 75 75
				75 75 75 75 75 75 75 75 75 75 75 75 75 75 75 75 75 75
				75 75 75>;

			PS_Config_Lmt_FW_Diff_N = <
				(-75) (-75) (-75) (-75) (-75) (-75) (-75) (-75) (-75) (-75) (-75) (-75) (-75) (-75) (-75) (-75) (-75) (-75)
				(-75) (-75) (-75) (-75) (-75) (-75) (-75) (-75) (-75) (-75) (-75) (-75) (-75) (-75) (-75) (-75) (-75) (-75)
				(-75) (-75) (-75) (-75) (-75) (-75) (-75) (-75) (-75) (-75) (-75) (-75) (-75) (-75) (-75) (-75) (-75) (-75)
				(-75) (-75) (-75) (-75) (-75) (-75) (-75) (-75) (-75) (-75) (-75) (-75) (-75) (-75) (-75) (-75) (-75) (-75)
				(-75) (-75) (-75) (-75) (-75) (-75) (-75) (-75) (-75) (-75) (-75) (-75) (-75) (-75) (-75) (-75) (-75) (-75)
				(-75) (-75) (-75) (-75) (-75) (-75) (-75) (-75) (-75) (-75) (-75) (-75) (-75) (-75) (-75) (-75) (-75) (-75)
				(-75) (-75) (-75) (-75) (-75) (-75) (-75) (-75) (-75) (-75) (-75) (-75) (-75) (-75) (-75) (-75) (-75) (-75)
				(-75) (-75) (-75) (-75) (-75) (-75) (-75) (-75) (-75) (-75) (-75) (-75) (-75) (-75) (-75) (-75) (-75) (-75)
				(-75) (-75) (-75) (-75) (-75) (-75) (-75) (-75) (-75) (-75) (-75) (-75) (-75) (-75) (-75) (-75) (-75) (-75)
				(-75) (-75) (-75) (-75) (-75) (-75) (-75) (-75) (-75) (-75) (-75) (-75) (-75) (-75) (-75) (-75) (-75) (-75)
				(-75) (-75) (-75) (-75) (-75) (-75) (-75) (-75) (-75) (-75) (-75) (-75) (-75) (-75) (-75) (-75) (-75) (-75)
				(-75) (-75) (-75) (-75) (-75) (-75) (-75) (-75) (-75) (-75) (-75) (-75) (-75) (-75) (-75) (-75) (-75) (-75)
				(-75) (-75) (-75) (-75) (-75) (-75) (-75) (-75) (-75) (-75) (-75) (-75) (-75) (-75) (-75) (-75) (-75) (-75)
				(-75) (-75) (-75) (-75) (-75) (-75) (-75) (-75) (-75) (-75) (-75) (-75) (-75) (-75) (-75) (-75) (-75) (-75)
				(-75) (-75) (-75) (-75) (-75) (-75) (-75) (-75) (-75) (-75) (-75) (-75) (-75) (-75) (-75) (-75) (-75) (-75)
				(-75) (-75) (-75) (-75) (-75) (-75) (-75) (-75) (-75) (-75) (-75) (-75) (-75) (-75) (-75) (-75) (-75) (-75)
				(-75) (-75) (-75) (-75) (-75) (-75) (-75) (-75) (-75) (-75) (-75) (-75) (-75) (-75) (-75) (-75) (-75) (-75)
				(-75) (-75) (-75) (-75) (-75) (-75) (-75) (-75) (-75) (-75) (-75) (-75) (-75) (-75) (-75) (-75) (-75) (-75)
				(-75) (-75) (-75) (-75) (-75) (-75) (-75) (-75) (-75) (-75) (-75) (-75) (-75) (-75) (-75) (-75) (-75) (-75)
				(-75) (-75) (-75) (-75) (-75) (-75) (-75) (-75) (-75) (-75) (-75) (-75) (-75) (-75) (-75) (-75) (-75) (-75)
				(-75) (-75) (-75) (-75) (-75) (-75) (-75) (-75) (-75) (-75) (-75) (-75) (-75) (-75) (-75) (-75) (-75) (-75)
				(-75) (-75) (-75) (-75) (-75) (-75) (-75) (-75) (-75) (-75) (-75) (-75) (-75) (-75) (-75) (-75) (-75) (-75)
				(-75) (-75) (-75) (-75) (-75) (-75) (-75) (-75) (-75) (-75) (-75) (-75) (-75) (-75) (-75) (-75) (-75) (-75)
				(-75) (-75) (-75) (-75) (-75) (-75) (-75) (-75) (-75) (-75) (-75) (-75) (-75) (-75) (-75) (-75) (-75) (-75)
				(-75) (-75) (-75) (-75) (-75) (-75) (-75) (-75) (-75) (-75) (-75) (-75) (-75) (-75) (-75) (-75) (-75) (-75)
				(-75) (-75) (-75) (-75) (-75) (-75) (-75) (-75) (-75) (-75) (-75) (-75) (-75) (-75) (-75) (-75) (-75) (-75)
				(-75) (-75) (-75) (-75) (-75) (-75) (-75) (-75) (-75) (-75) (-75) (-75) (-75) (-75) (-75) (-75) (-75) (-75)
				(-75) (-75) (-75) (-75) (-75) (-75) (-75) (-75) (-75) (-75) (-75) (-75) (-75) (-75) (-75) (-75) (-75) (-75)
				(-75) (-75) (-75) (-75) (-75) (-75) (-75) (-75) (-75) (-75) (-75) (-75) (-75) (-75) (-75) (-75) (-75) (-75)
				(-75) (-75) (-75) (-75) (-75) (-75) (-75) (-75) (-75) (-75) (-75) (-75) (-75) (-75) (-75) (-75) (-75) (-75)
				(-75) (-75) (-75) (-75) (-75) (-75) (-75) (-75) (-75) (-75) (-75) (-75) (-75) (-75) (-75) (-75) (-75) (-75)
				(-75) (-75) (-75) (-75) (-75) (-75) (-75) (-75) (-75) (-75) (-75) (-75) (-75) (-75) (-75) (-75) (-75) (-75)
				(-75) (-75) (-75) (-75) (-75) (-75) (-75) (-75) (-75) (-75) (-75) (-75) (-75) (-75) (-75) (-75) (-75) (-75)
				(-75) (-75) (-75) (-75) (-75) (-75) (-75) (-75) (-75) (-75) (-75) (-75) (-75) (-75) (-75) (-75) (-75) (-75)
				(-75) (-75) (-75) (-75) (-75) (-75) (-75) (-75) (-75) (-75) (-75) (-75) (-75) (-75) (-75) (-75) (-75) (-75)
				(-75) (-75) (-75) (-75) (-75) (-75) (-75) (-75) (-75) (-75) (-75) (-75) (-75) (-75) (-75) (-75) (-75) (-75)
				(-75) (-75) (-75)>;

			PS_Config_Diff_Test_Frame = <50>;
		};
	};
};
